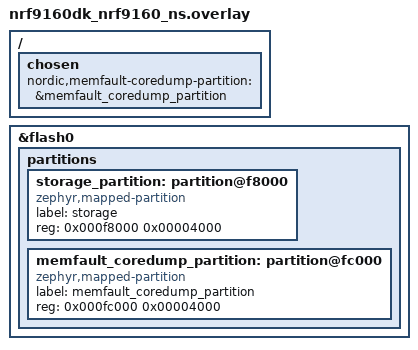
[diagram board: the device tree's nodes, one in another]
/*
 * Copyright (c) 2026 Nordic Semiconductor ASA
 *
 * SPDX-License-Identifier: LicenseRef-Nordic-5-Clause
 */

#include <samples/cellular/nrf91_no_bootloader_partitions.dtsi>

#include <samples/cellular/nrf91_sram_partitions.dtsi>

/* The internal-flash coredump backend (CONFIG_MEMFAULT_NCS_INTERNAL_FLASH_BACKED_COREDUMP)
 * memory-maps the coredump partition and reads it with memcpy(), so it must live in
 * internal flash (not on the external mx25r64). Carve it out of the storage region.
 */
/delete-node/ &storage_partition;

&flash0 {
	partitions {
		storage_partition: partition@f8000 {
			compatible = "zephyr,mapped-partition";
			label = "storage";
			reg = <0x000f8000 0x00004000>;
		};

		memfault_coredump_partition: partition@fc000 {
			compatible = "zephyr,mapped-partition";
			label = "memfault_coredump_partition";
			reg = <0x000fc000 0x00004000>;
		};
	};
};

/ {
	chosen {
		nordic,memfault-coredump-partition = &memfault_coredump_partition;
	};
};
